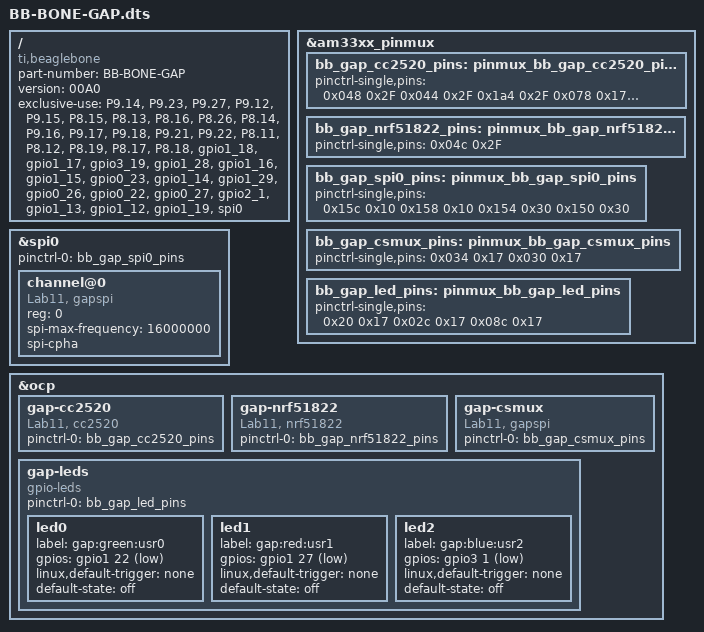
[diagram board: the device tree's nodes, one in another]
/*
 * Copyright (C) 2014 Neal Jackson, LAB11
 *
 * Cape for LAB11 GAP radio platform.
 *
 * This program is free software; you can redistribute it and/or modify
 * it under the terms of the GNU General Public License version 2 as
 * published by the Free Software Foundation.
 */

/dts-v1/;
/plugin/;

/ {
   	compatible = "ti,beaglebone", "ti,beaglebone-black";

        /* identification */
        part-number = "BB-BONE-GAP";
        version = "00A0";

        /* state the resources this cape uses */
        exclusive-use =
                /* the pin header uses */

                /* CC2520 GPIO */
                "P9.14",       /* SFD0:  gpio1_18 */
                "P9.23",       /* FIFP0: gpio1_17 */
                "P9.27",       /* FIFO0: gpio3_19 */
                "P9.12",       /* RST0:  gpio1_28 */
                "P9.15",       /* CCA0:  gpio1_16 */

                "P8.15",       /* SFD1:  gpio1_15 */
                "P8.13",       /* FIFP1: gpio0_23 */
                "P8.16",       /* FIFO1: gpio1_14 */
                "P8.26",       /* RST1:  gpio1_29 */
                "P8.14",       /* CCA1:  gpio0_26 */

                /* NRF51822 GPIO */
                "P9.16",       /* BIRQ: gpio1_19  */

                /* SPI */
                "P9.17",       /* CS:   spi0_cs0  */
                "P9.18",       /* MOSI: spi0_d1   */
                "P9.21",       /* MISO: spi0_d0   */
                "P9.22",       /* SCLK: spi0_sclk */

                /* CHIP SELECT MUX */
                "P8.11",       /* SPIE0: gpio1_13 */
                "P8.12",       /* SPIE1: gpio1_12 */

                /* LEDS */
                "P8.19",       /* LED0: gpio0_22  */
                "P8.17",       /* LED1: gpio0_27  */
                "P8.18",       /* LED2: gpio2_1   */

                /* the hardware ip uses */
                "gpio1_18",
                "gpio1_17",
                "gpio3_19",
                "gpio1_28",
                "gpio1_16",
                "gpio1_15",
                "gpio0_23",
                "gpio1_14",
                "gpio1_29",
                "gpio0_26",
                "gpio0_22",
                "gpio0_27",
                "gpio2_1",
                "gpio1_13",
                "gpio1_12",
                "gpio1_19",
                "spi0";

        fragment@0 {
                target = <&am33xx_pinmux>;
                __overlay__ {
                        bb_gap_cc2520_pins: pinmux_bb_gap_cc2520_pins {
                        		pinctrl-single,pins = <
                                        0x048 0x2F /* ehrpwm1a.gpio1_18, INPUT         | MODE7 */
                                        0x044 0x2F /* gpio1_17.gpio1_17, INPUT         | MODE7 */
                                        0x1a4 0x2F /* gpio3_19.gpio3_19, INPUT         | MODE7 */
                                        0x078 0x17 /* gpio1_28.gpio1_28, OUTPUT_PULLUP | MODE7 */
                                        0x040 0x2F /* gpio1_16.gpio1_16, INPUT         | MODE7 */

                                        0x03c 0x2F /* gpio1_15.gpio1_15, INPUT         | MODE7 */
                                        0x024 0x2F /* ehrpwm2b.gpio0_23, INPUT         | MODE7 */
                                        0x038 0x2F /* gpio1_14.gpio1_14, INPUT         | MODE7 */
                                        0x07c 0x17 /* gpio1_29.gpio1_29, OUTPUT_PULLUP | MODE7 */
                                        0x028 0x2F /* gpio0_26.gpio0_26, INPUT         | MODE7 */
                                >;
                        };
                        bb_gap_nrf51822_pins: pinmux_bb_gap_nrf51822_pins {
                                pinctrl-single,pins = <
                                        0x04c 0x2F /* ehrpwm1b.gpio1_19, INPUT | MODE7 */
                                >;
                        };
                        bb_gap_spi0_pins: pinmux_bb_gap_spi0_pins {
                                pinctrl-single,pins = <
                                        0x15c 0x10 /* i2c1_scl.spi0_cs0,   OUTPUT_PULLUP | MODE0 */
                                        0x158 0x10 /* i2c1_sda.spi0_d1,    OUTPUT_PULLUP | MODE0 */
                                        0x154 0x30 /* uart2_txd.spi0_d0,   INPUT_PULLUP  | MODE0 */
                                        0x150 0x30 /* uart2_rxd.spi0_sclk, INPUT_PULLUP  | MODE0 */
                                >;
                        };
                        bb_gap_csmux_pins: pinmux_bb_gap_csmux_pins {
                                pinctrl-single,pins = <
                                        0x034 0x17 /* gpio1_13.gpio1_13, OUTPUT_PULLUP | MODE7 */
                                        0x030 0x17 /* gpio1_12.gpio1_12, OUTPUT_PULLUP | MODE7 */
                                >;
                        };
                        bb_gap_led_pins: pinmux_bb_gap_led_pins {
                                pinctrl-single,pins = <
                                        0x20 0x17  /* ehrpwm2a.gpio0_22, OUTPUT_PULLUP | MODE7 */
                                        0x02c 0x17 /* gpio0_27.gpio0_27, OUTPUT_PULLUP | MODE7 */
                                        0x08c 0x17 /* gpio2_1.gpio2_1,   OUTPUT_PULLUP | MODE7 */
                                >;
                        };
                };
        };

		fragment@1 {
                target = <&spi0>;	/* spi0 is numbered correctly */
                __overlay__ {
                		#address-cells = <1>;
                		#size-cells = <0>;

                        status = "okay";
                        pinctrl-names = "default";
                        pinctrl-0 = <&bb_gap_spi0_pins>;

                        channel@0 {
                        	#address-cells = <1>;
                        	#size-cells = <0>;

                        	compatible = "Lab11, gapspi";

                        	reg = <0>;
                        	spi-max-frequency = <16000000>;
                        	spi-cpha;
                        };
                };
        };

        fragment@2 {
        		target = <&ocp>;
        		__overlay__ {

        				gap-cc2520 {
        					compatible = "Lab11, cc2520";
                            pinctrl-names = "default";
        					pinctrl-0 = <&bb_gap_cc2520_pins>;
                            status = "okay";
        				};
        		};
        };

        fragment@3 {
                target = <&ocp>;
                __overlay__ {

                        gap-nrf51822 {
                            compatible = "Lab11, nrf51822";
                            pinctrl-names = "default";
                            pinctrl-0 = <&bb_gap_nrf51822_pins>;
                            status = "okay";
                        };
                };
        };

        fragment@4 {
                target = <&ocp>;
                __overlay__ {

                        gap-csmux {
                            compatible = "Lab11, gapspi";
                            pinctrl-names = "default";
                            pinctrl-0 = <&bb_gap_csmux_pins>;
                            status = "okay";
                        };
                };
        };

        fragment@5 {
                target = <&ocp>;
                __overlay__ {

                        gap-leds {
                            compatible = "gpio-leds";
                            pinctrl-names = "default";
                            pinctrl-0 = <&bb_gap_led_pins>;
                            status = "okay";

                            led0 {
                                label = "gap:green:usr0";
                                gpios = <&gpio1 22 1>; /* Active low */
                                linux,default-trigger = "none";
                                default-state = "off";
                            };

                            led1 {
                                label = "gap:red:usr1";
                                gpios = <&gpio1 27 1>;
                                linux,default-trigger = "none";
                                default-state = "off";
                            };

                            led2 {
                                label = "gap:blue:usr2";
                                gpios = <&gpio3 1 1>;
                                linux,default-trigger = "none";
                                default-state = "off";
                            };
                        };
                };
        };
};
